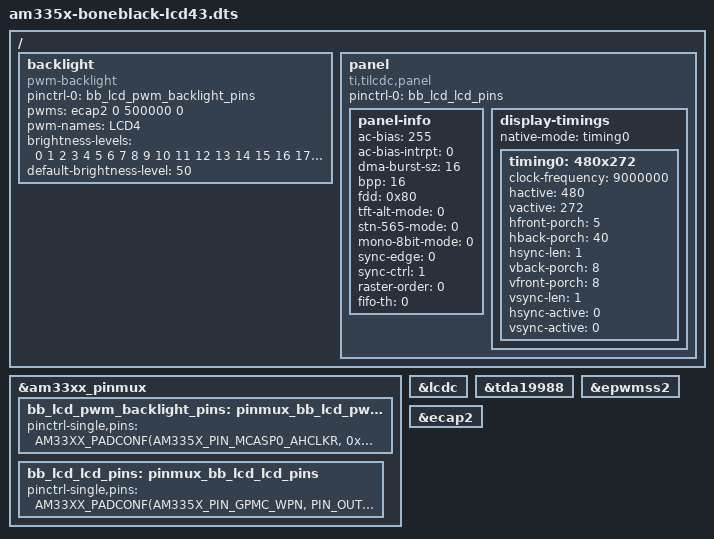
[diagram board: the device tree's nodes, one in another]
/*
 * Copyright (C) 2012 Texas Instruments Incorporated - http://www.ti.com/
 *
 * This program is free software; you can redistribute it and/or modify
 * it under the terms of the GNU General Public License version 2 as
 * published by the Free Software Foundation.
 *
 * Copyright (C) 2019-2021 Bootlin SAS - https://bootlin.com
 * Adapted from DT overlay sources for the 4.3" cape from Element14
 * https://www.element14.com/bbcape43
 */
/dts-v1/;

#include "am335x-boneblack.dts"

/ {
			backlight {
				compatible      = "pwm-backlight";
				pinctrl-names   = "default";
				pinctrl-0       = <&bb_lcd_pwm_backlight_pins>;

				pwms = <&ecap2 0 500000 0>;
				pwm-names = "LCD4";
				brightness-levels = <0 1 2 3 4 5 6 7 8 9 10 11 12 13 14 15 16 17 18 19 20 21 22 23 24 25 26 27 28 29 30 31 32 33 34 35 36 37 38 39 40 41 42 43 44 45 46 47 48 49 50 51 52 53 54 55 56 57 58 59 60 61 62 63 64 65 66 67 68 69 70 71 72 73 74 75 76 77 78 79 80 81 82 83 84 85 86 87 88 89 90 91 92 93 94 95 96 97 98 99 100>;
				default-brightness-level = <50>; /* index to the array above */
				status = "okay";
			};

			/* Settings for NHD-4.3-ATXI#-T-1 / LCD4 cape: */
			panel {
				compatible = "ti,tilcdc,panel";
				pinctrl-names = "default";
				pinctrl-0 = <&bb_lcd_lcd_pins>;
				status = "okay";
				panel-info {
					ac-bias           = <255>;
					ac-bias-intrpt    = <0>;
					dma-burst-sz      = <16>;
					bpp               = <16>;
					fdd               = <0x80>;
					tft-alt-mode      = <0>;
					stn-565-mode      = <0>;
					mono-8bit-mode    = <0>;
					sync-edge         = <0>;
					sync-ctrl         = <1>;
					raster-order      = <0>;
					fifo-th           = <0>;
				};
				display-timings {
					native-mode = <&timing0>;
					timing0: 480x272 {
						clock-frequency = <9000000>;
						hactive = <480>;
						vactive = <272>;
						hfront-porch = <5>;
						hback-porch = <40>;
						hsync-len = <1>;
						vback-porch = <8>;
						vfront-porch = <8>;
						vsync-len = <1>;
						hsync-active = <0>;
						vsync-active = <0>;
					};
				};
			};
};

&am33xx_pinmux {
			bb_lcd_pwm_backlight_pins: pinmux_bb_lcd_pwm_backlight_pins {
				pinctrl-single,pins = <
				AM33XX_PADCONF(AM335X_PIN_MCASP0_AHCLKR, 0x0, MUX_MODE4) /* mcasp0_ahclkr.eCAP2_in_PWM2_out */
				>;
			};

			bb_lcd_lcd_pins: pinmux_bb_lcd_lcd_pins {
				pinctrl-single,pins = <
                        /* Bootlin boot time labs: use idle pin as custom GPIO on P9_13 */
			AM33XX_PADCONF(AM335X_PIN_GPMC_WPN, PIN_OUTPUT, MUX_MODE7)

                        AM33XX_PADCONF(AM335X_PIN_LCD_DATA0, PIN_OUTPUT, MUX_MODE0)                     /* lcd_data0 */
                        AM33XX_PADCONF(AM335X_PIN_LCD_DATA1, PIN_OUTPUT, MUX_MODE0)                     /* lcd_data1 */
                        AM33XX_PADCONF(AM335X_PIN_LCD_DATA2, PIN_OUTPUT, MUX_MODE0)                     /* lcd_data2 */
                        AM33XX_PADCONF(AM335X_PIN_LCD_DATA3, PIN_OUTPUT, MUX_MODE0)                     /* lcd_data3 */
                        AM33XX_PADCONF(AM335X_PIN_LCD_DATA4, PIN_OUTPUT, MUX_MODE0)                     /* lcd_data4 */
                        AM33XX_PADCONF(AM335X_PIN_LCD_DATA5, PIN_OUTPUT, MUX_MODE0)                     /* lcd_data5 */
                        AM33XX_PADCONF(AM335X_PIN_LCD_DATA6, PIN_OUTPUT, MUX_MODE0)                     /* lcd_data6 */
                        AM33XX_PADCONF(AM335X_PIN_LCD_DATA7, PIN_OUTPUT, MUX_MODE0)                     /* lcd_data7 */
                        AM33XX_PADCONF(AM335X_PIN_LCD_DATA8, PIN_OUTPUT, MUX_MODE0)                     /* lcd_data8 */
                        AM33XX_PADCONF(AM335X_PIN_LCD_DATA9, PIN_OUTPUT, MUX_MODE0)                     /* lcd_data9 */
                        AM33XX_PADCONF(AM335X_PIN_LCD_DATA10, PIN_OUTPUT, MUX_MODE0)                    /* lcd_data10 */
                        AM33XX_PADCONF(AM335X_PIN_LCD_DATA11, PIN_OUTPUT, MUX_MODE0)                    /* lcd_data11 */
                        AM33XX_PADCONF(AM335X_PIN_LCD_DATA12, PIN_OUTPUT, MUX_MODE0)                    /* lcd_data12 */
                        AM33XX_PADCONF(AM335X_PIN_LCD_DATA13, PIN_OUTPUT, MUX_MODE0)                    /* lcd_data13 */
                        AM33XX_PADCONF(AM335X_PIN_LCD_DATA14, PIN_OUTPUT, MUX_MODE0)                    /* lcd_data14 */
                        AM33XX_PADCONF(AM335X_PIN_LCD_DATA15, PIN_OUTPUT, MUX_MODE0)                    /* lcd_data15 */
                        AM33XX_PADCONF(AM335X_PIN_LCD_VSYNC, PIN_OUTPUT, MUX_MODE0)                     /* lcd_vsync */
                        AM33XX_PADCONF(AM335X_PIN_LCD_HSYNC, PIN_OUTPUT, MUX_MODE0)                     /* lcd_hsync */
                        AM33XX_PADCONF(AM335X_PIN_LCD_PCLK, PIN_OUTPUT, MUX_MODE0)                      /* lcd_pclk */
                        AM33XX_PADCONF(AM335X_PIN_LCD_AC_BIAS_EN, PIN_OUTPUT, MUX_MODE0)                /* lcd_ac_bias_en */
				>;
			};
};

&lcdc {
			/delete-node/ port;
};

&tda19988 {
			/delete-node/ ports;
};

&epwmss2 {
			/* Parent to ecap */
			status = "okay";
};

&ecap2 {
			status = "okay";
};

&lcdc {
			status = "okay";
};
